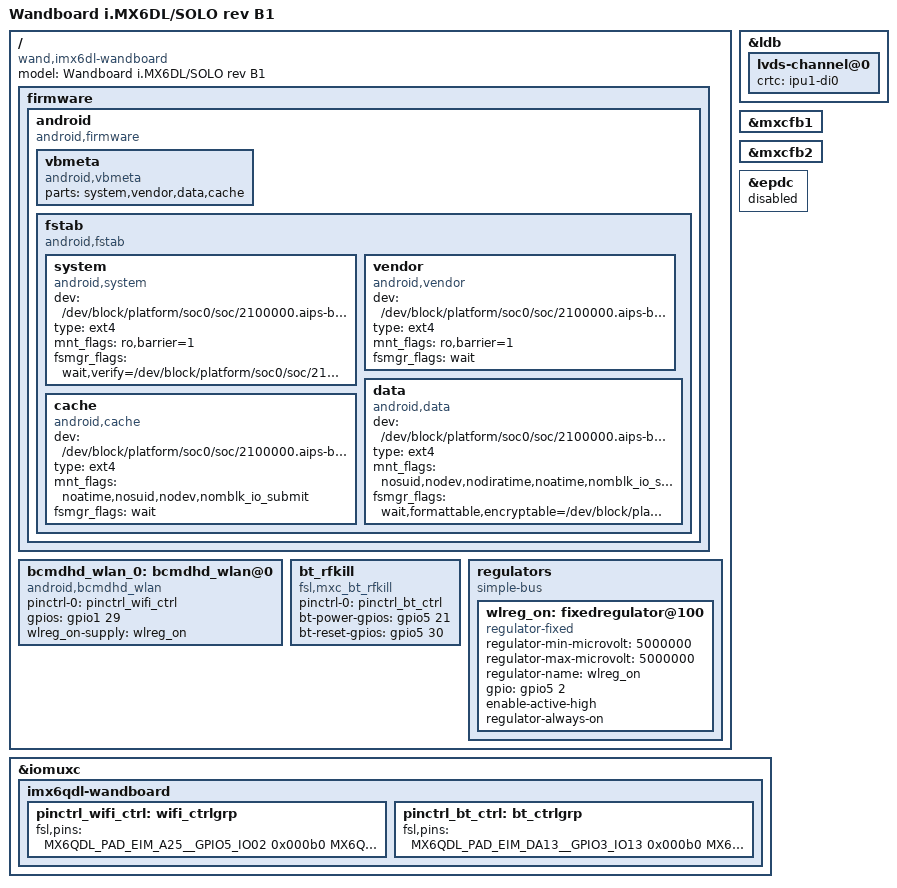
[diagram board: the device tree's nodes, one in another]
/*
 * Copyright 2013 Freescale Semiconductor, Inc.
 *
 * Author: Fabio Estevam <fabio.estevam@freescale.com>
 *
 * This program is free software; you can redistribute it and/or modify
 * it under the terms of the GNU General Public License version 2 as
 * published by the Free Software Foundation.
 *
 */
/dts-v1/;
#include "imx6dl.dtsi"
#include "imx6qdl-wandboard.dtsi"

/ {
	model = "Wandboard i.MX6DL/SOLO rev B1";
	compatible = "wand,imx6dl-wandboard", "fsl,imx6dl";
	firmware {
		android {
			compatible = "android,firmware";
			vbmeta {
				compatible = "android,vbmeta";
				parts = "system,vendor,data,cache";
			};
			fstab {
				compatible = "android,fstab";
					system {
						compatible = "android,system";
						dev = "/dev/block/platform/soc0/soc/2100000.aips-bus/2198000.usdhc/by-name/system";
						type = "ext4";
						mnt_flags = "ro,barrier=1";
						fsmgr_flags = "wait,verify=/dev/block/platform/soc0/soc/2100000.aips-bus/2198000.usdhc/by-name/metadata";
					};
					vendor {
						compatible = "android,vendor";
						dev = "/dev/block/platform/soc0/soc/2100000.aips-bus/2198000.usdhc/by-name/vendor";
						type = "ext4";
						mnt_flags = "ro,barrier=1";
						fsmgr_flags = "wait";
					};
					data {
						compatible = "android,data";
						dev = "/dev/block/platform/soc0/soc/2100000.aips-bus/2198000.usdhc/by-name/userdata";
						type = "ext4";
						mnt_flags = "nosuid,nodev,nodiratime,noatime,nomblk_io_submit,noauto_da_alloc,errors=panic";
						fsmgr_flags = "wait,formattable,encryptable=/dev/block/platform/soc0/soc/2100000.aips-bus/2198000.usdhc/by-name/datafooter,quota";
					};
					cache {
						compatible = "android,cache";
						dev = "/dev/block/platform/soc0/soc/2100000.aips-bus/2198000.usdhc/by-name/cache";
						type = "ext4";
						mnt_flags = "noatime,nosuid,nodev,nomblk_io_submit";
						fsmgr_flags = "wait";
					};
			};
		};
	};

	bcmdhd_wlan_0: bcmdhd_wlan@0 {
		compatible = "android,bcmdhd_wlan";
		pinctrl-names = "default";
		pinctrl-0 = <&pinctrl_wifi_ctrl>;
		gpios = <&gpio1 29 0>;    /* WL_HOST_WAKE */
		status = "okay";
		wlreg_on-supply = <&wlreg_on>;
	};

	bt_rfkill {
		compatible = "fsl,mxc_bt_rfkill";
		pinctrl-names = "default";
		pinctrl-0 = <&pinctrl_bt_ctrl>;
		bt-power-gpios = <&gpio5 21 0>;
		bt-reset-gpios = <&gpio5 30 0>;
		status ="okay";
	};

	regulators {
		compatible = "simple-bus";
		#address-cells = <1>;
		#size-cells = <0>;

		wlreg_on: fixedregulator@100 {
			compatible = "regulator-fixed";
			regulator-min-microvolt = <5000000>;
			regulator-max-microvolt = <5000000>;
			regulator-name = "wlreg_on";
			gpio = <&gpio5 2 GPIO_ACTIVE_HIGH>;
			enable-active-high;
			regulator-always-on;
		};
	};

};

&ldb {
	lvds-channel@0 {
		crtc = "ipu1-di0";
	};
};

&mxcfb1 {
	status = "okay";
};

&mxcfb2 {
	status = "okay";
};

#if 0
&mxcfb3 {
	status = "okay";
};

&mxcfb4 {
	status = "okay";
};
#endif

&epdc {
	status = "disabled";
};

&iomuxc {
	pinctrl-names = "default";

	imx6qdl-wandboard {

		pinctrl_wifi_ctrl: wifi_ctrlgrp {
			fsl,pins = <
				MX6QDL_PAD_EIM_A25__GPIO5_IO02	  0x000b0			/* wifi-reset */
				MX6QDL_PAD_EIM_EB1__GPIO2_IO29	  0x000b0			/* wifi-on */
				MX6QDL_PAD_ENET_RXD1__GPIO1_IO26  0x000b0			/* wifi-reg */
				MX6QDL_PAD_ENET_TXD1__GPIO1_IO29  0x80000000		/* wifi-host-wake */

			>;
		};

		pinctrl_bt_ctrl: bt_ctrlgrp {
			fsl,pins = <
				MX6QDL_PAD_EIM_DA13__GPIO3_IO13		0x000b0		/* bluetooth-reg-on */
				MX6QDL_PAD_EIM_DA14__GPIO3_IO14		0x80000000	/* bluetooth-wake */
				MX6QDL_PAD_EIM_DA15__GPIO3_IO15		0x80000000	/* bluetooth-host-wake */
			>;
		};
	};
};
